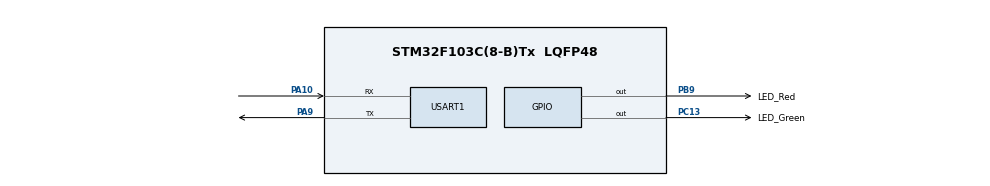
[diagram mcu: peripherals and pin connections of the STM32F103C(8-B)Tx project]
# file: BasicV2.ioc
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Mcu.Family=STM32F1
Mcu.Name=STM32F103C(8-B)Tx
Mcu.Package=LQFP48
NVIC.PriorityGroup=NVIC_PRIORITYGROUP_4
PA10.Mode=Asynchronous
PA10.Signal=USART1_RX
PA9.Mode=Asynchronous
PA9.Signal=USART1_TX
PB9.GPIO_Label=LED_Red
PB9.Signal=GPIO_Output
PC13-TAMPER-RTC.GPIO_Label=LED_Green
PC13-TAMPER-RTC.Signal=GPIO_Output
PC14-OSC32_IN.Mode=LSE-External-Oscillator
PC14-OSC32_IN.Signal=RCC_OSC32_IN
PC15-OSC32_OUT.Mode=LSE-External-Oscillator
PC15-OSC32_OUT.Signal=RCC_OSC32_OUT
PD0-OSC_IN.Mode=HSE-External-Oscillator
PD0-OSC_IN.Signal=RCC_OSC_IN
PD1-OSC_OUT.Mode=HSE-External-Oscillator
PD1-OSC_OUT.Signal=RCC_OSC_OUT
ProjectManager.HeapSize=0x200
ProjectManager.StackSize=0x400
ProjectManager.TargetToolchain=SW4STM32
RCC.APB1Freq_Value=8000000
RCC.APB2Freq_Value=8000000
RCC.SYSCLKSource=RCC_SYSCLKSOURCE_HSE
USART1.VirtualMode=VM_ASYNC
VP_SYS_VS_ND.Mode=No_Debug
board=custom

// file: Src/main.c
/* USER CODE BEGIN Header */
/**
  ******************************************************************************
  * @file           : main.c
  * @brief          : Main program body
  ******************************************************************************
  * @attention
  *
  * <h2><center>&copy; Copyright (c) 2020 STMicroelectronics.
  * All rights reserved.</center></h2>
  *
  * This software component is licensed by ST under BSD 3-Clause license,
  * the "License"; You may not use this file except in compliance with the
  * License. You may obtain a copy of the License at:
  *                        opensource.org/licenses/BSD-3-Clause
  *
  ******************************************************************************
  */
/* USER CODE END Header */

#include "main.h"
#include "usart.h"
#include "gpio.h"

/* USER CODE BEGIN Includes */
#include "../HWint/sleep.h"
/* USER CODE END Includes */

void SystemClock_Config(void);

int main(void)
{

  /* MCU Configuration--------------------------------------------------------*/

  /* Reset of all peripherals, Initializes the Flash interface and the Systick. */

  LL_APB2_GRP1_EnableClock(LL_APB2_GRP1_PERIPH_AFIO);
  LL_APB1_GRP1_EnableClock(LL_APB1_GRP1_PERIPH_PWR);

  NVIC_SetPriorityGrouping(NVIC_PRIORITYGROUP_4);

  /* System interrupt init*/

  /** DISABLE: JTAG-DP Disabled and SW-DP Disabled
  */
  LL_GPIO_AF_DisableRemap_SWJ();

  /* Configure the system clock */
  SystemClock_Config();

  /* Initialize all configured peripherals */
  MX_GPIO_Init();
  MX_USART1_UART_Init();

  /* Infinite loop */
  /* USER CODE BEGIN WHILE */
  while (1)
  {
	  LL_GPIO_ResetOutputPin(LED_Green_GPIO_Port, LED_Green_Pin);
	  LL_GPIO_SetOutputPin(LED_Red_GPIO_Port, LED_Red_Pin);

	  for(volatile uint64_t Cnt = 0; Cnt < 0xF000; Cnt++);
    /* USER CODE END WHILE */

    /* USER CODE BEGIN 3 */
	  LL_GPIO_SetOutputPin(LED_Green_GPIO_Port, LED_Green_Pin);
	  LL_GPIO_ResetOutputPin(LED_Red_GPIO_Port, LED_Red_Pin);

	  for(volatile uint64_t Cnt = 0; Cnt < 0xF000; Cnt++);

	  LL_USART_TransmitData8(USART1, 'Y');
	  Sleep();
  }
  /* USER CODE END 3 */
}

void SystemClock_Config(void)
{
  LL_FLASH_SetLatency(LL_FLASH_LATENCY_0);

  if(LL_FLASH_GetLatency() != LL_FLASH_LATENCY_0)
  {
    Error_Handler();
  }
  LL_RCC_HSE_Enable();

   /* Wait till HSE is ready */
  while(LL_RCC_HSE_IsReady() != 1)
  {

  }
  LL_RCC_SetAHBPrescaler(LL_RCC_SYSCLK_DIV_1);
  LL_RCC_SetAPB1Prescaler(LL_RCC_APB1_DIV_1);
  LL_RCC_SetAPB2Prescaler(LL_RCC_APB2_DIV_1);
  LL_RCC_SetSysClkSource(LL_RCC_SYS_CLKSOURCE_HSE);

   /* Wait till System clock is ready */
  while(LL_RCC_GetSysClkSource() != LL_RCC_SYS_CLKSOURCE_STATUS_HSE)
  {

  }
  LL_Init1msTick(8000000);
  LL_SYSTICK_SetClkSource(LL_SYSTICK_CLKSOURCE_HCLK);
  LL_SetSystemCoreClock(8000000);
}

void Error_Handler(void)
{
}

/************************ (C) COPYRIGHT STMicroelectronics *****END OF FILE****/
